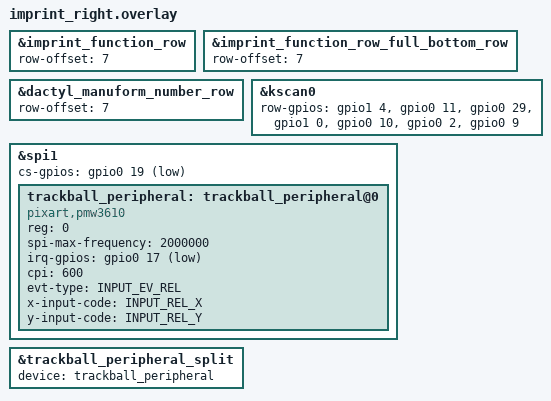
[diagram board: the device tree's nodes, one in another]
#include "imprint.dtsi"

&imprint_function_row { // The matrix transform for this board is 7 rows down because the left half is 7 rows tall according to the matrix.
    row-offset = <7>;
};

&imprint_function_row_full_bottom_row { // The matrix transform for this board is 7 rows down because the left half is 7 rows tall according to the matrix.
    row-offset = <7>;
};

&dactyl_manuform_number_row {
    row-offset = <7>;
};

&kscan0 {
    row-gpios
        = <&gpio1 4 GPIO_ACTIVE_HIGH> // row0 from schematic
        , <&gpio0 11 GPIO_ACTIVE_HIGH> // row1 from schematic
        , <&gpio0 29 GPIO_ACTIVE_HIGH> // row2 from schematic
        , <&gpio1 0 GPIO_ACTIVE_HIGH> // row3 from schematic
        , <&gpio0 10 GPIO_ACTIVE_HIGH> // row4 from schematic
        , <&gpio0 2 GPIO_ACTIVE_HIGH> // row5 from schematic
        , <&gpio0 9 GPIO_ACTIVE_HIGH> // row6 from schematic
        ;
};

#include <zephyr/dt-bindings/input/input-event-codes.h>
&spi1 {
    cs-gpios = <&gpio0 19 GPIO_ACTIVE_LOW>;

    trackball_peripheral: trackball_peripheral@0 {
        status = "okay";
        compatible = "pixart,pmw3610";
        reg = <0>;
        spi-max-frequency = <2000000>;
        irq-gpios = <&gpio0 17 (GPIO_ACTIVE_LOW | GPIO_PULL_UP)>;
        cpi = <600>;
        evt-type = <INPUT_EV_REL>;
        x-input-code = <INPUT_REL_X>;
        y-input-code = <INPUT_REL_Y>;
    };
};

// Overrides for the input-split child node
&trackball_peripheral_split {
    device = <&trackball_peripheral>;
};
